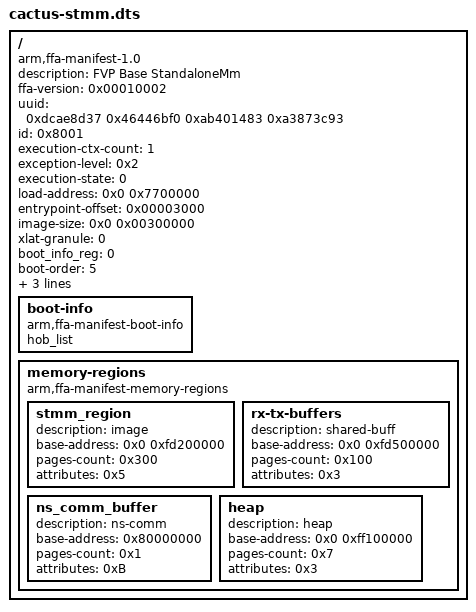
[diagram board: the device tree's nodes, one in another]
/*
 * Copyright (c) 2024, Arm Limited and Contributors. All rights reserved.
 *
 * SPDX-License-Identifier: BSD-3-Clause
 */

/dts-v1/;

/ {

	/*
	 * FF-A compatible Secure Partition Manager parses the
	 * config file and fetch the following booting arguments to
	 * pass on to the StandAloneMM(StMM) Secure Partition.
	 */
	compatible = "arm,ffa-manifest-1.0";

	description = "FVP Base StandaloneMm";
	ffa-version = <0x00010002>; /* 31:16 - Major, 15:0 - Minor */
	uuid = <0xdcae8d37 0x46446bf0 0xab401483 0xa3873c93>;
	id = <0x8001>;
	execution-ctx-count = <1>;
	exception-level = <0x2>; /* SEL1*/
	execution-state = <0>; /* AArch64*/
	load-address = <0x0 0x7700000>;
	entrypoint-offset = <0x00003000>; /*Image after manifest and HOB list. */
	image-size = <0x0 0x00300000>;
	xlat-granule = <0>; /* 4KiB */
	boot_info_reg = <0>; /* x0 */
	boot-order = <5>;
	messaging-method = <0x3>;
	power-management-messages = <0>;
	gp-register-num = <0>;

	/* Boot Info */
	boot-info {
		compatible = "arm,ffa-manifest-boot-info";
		hob_list;
	};

	/*
	 * Device regions of StMM manifest not included, given they
	 * are not used in the hob.
	 */
	memory-regions {
		compatible = "arm,ffa-manifest-memory-regions";
		/*
		 * SPM Payload memory. Mapped as code region for S-EL0
		 * Similar to ARM_SP_IMAGE_MMAP.
		 */
		stmm_region {
			description = "image";
			base-address = <0x0 0xfd200000>;
			pages-count = <0x300>;
			/* StMM will remap the regions during runtime */
			attributes = <0x5>;
		};

		/*
		 * Memory shared between EL3 and S-EL0.
		 * Similar to ARM_SPM_BUF_EL0_MMAP.
		 */
		rx-tx-buffers {
			description = "shared-buff";
			base-address = <0x0 0xfd500000>;
			pages-count = <0x100>;
			attributes = <0x3>;
		};

		/*
		 * Memory shared between Normal world and S-EL0.
		 * Similar to ARM_SP_IMAGE_NS_BUF_MMAP.
		 */
		ns_comm_buffer {
			/*
			 * Description is needed for StMM to identify
			 * ns-communication buffer.
			 */
			description = "ns-comm";
			base-address = <0x80000000>;
			pages-count = <0x1>;
			attributes = <0xB>;
		};

		/*
		 * Heap used by SP to allocate memory for DMA.
		 */
		heap {
			/*
			 * Description is needed for StMM to identify
			 * heap buffer.
			 */
			description = "heap";
			base-address = <0x0 0xff100000>;
			pages-count = <0x7>;
			attributes = <0x3>;
		};
	};
};

